# apollo510 register map
Vendor: Ambiq Micro; Series: Apollo; File version: 1.0
CPU: CM55 r1p1, little endian, MPU, FPU, double-precision FPU, DSP, I-cache, D-cache, VTOR, ITCM, DTCM, 4 interrupt priority bits, 0 interrupts, 8 SAU regions
Registers are 32-bit, read-write, reset 0x0 unless marked. A register's access mark holds for its fields unless they carry their own. Offsets are from the block's base; [hi:lo] are bit positions; {n}, {i} and the like mark numbered series.

## DSI — Digital Serial Interface Unit
Base 0x400A8000
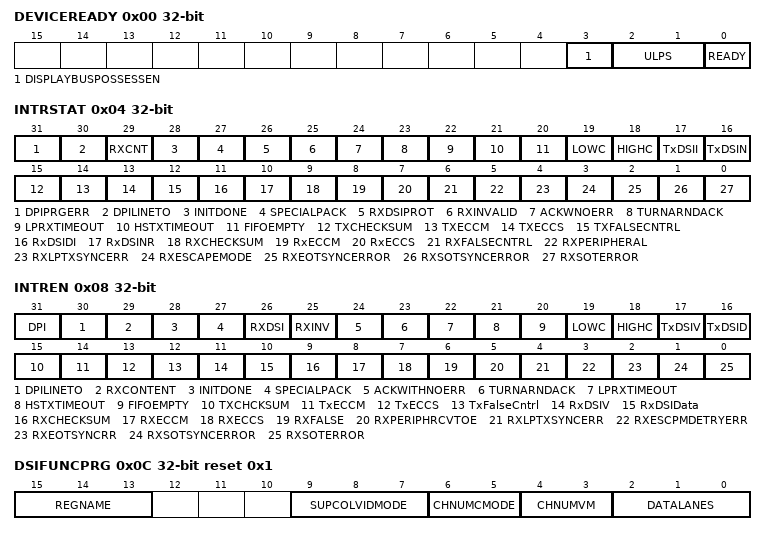
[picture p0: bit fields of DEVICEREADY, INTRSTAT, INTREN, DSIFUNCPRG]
0x00 DEVICEREADY — Devide Ready register
  [3] DISPLAYBUSPOSSESSEN — Inform DSI receiver has to be given the bus possession for receiving the tearing effect trigger message; Reset by the processor to stop the bus possession of the DSI receiver; Note: Tearing effect is supported only in Type1; Display Architecture (command mode only) as suggested by Display Command Set Specification; Note1: Even if the processor does not clear the display_bus_possession bit after receiving the interrupt for tearing effect, DSI-tx controller starts the activities on the DSI link once the TE trigger message is received
  [2:1] ULPS — FIXME - Bitfield description needed here.
    2=LOW_POWER (This pattern is set by the processor to inform that entire DSI host is to be put on ultra low power [POWER SAVING] mode 01 - This pattern is set by the processor to inform); 1=EXIT (This pattern is set by the processor to inform that entire DSI host is to be pu on ultr low power EXIT mode); 0=This (pattern is set by the processor to make the DSI host come out of the wakeup time and resume the normal operation if the DSI Host already remains in the ULPS exit state. S/W needs to ensure that there is a minimum of 1ms time available before clearing the UPLS exit State. 1(a). In DPI Only Mode: No DPI traffic should be sent after the above patterns like 10 or 01 is set in this register. Device_ready bit in Device Ready register should not be disturbed or should remain set while the device is subjected to ULPS states. 1(b). In Dual Display Mode: DPI Interface has to be disabled and also no DBI traffic should be sent after the above patterns like 10 or 01 is set in this register. Device_ready bit in Device Ready register should not be disturbed or should remain set while the device is subjected to ULPS states.)
  [0] READY — Ready for programming after all count registers and timeout.
    1=PROGRAMMED (Set to 1 after dphy_parameter register, all the count registers, and timeout and interrupt enable registers are being programmed.); 0=READY (Set by the processor to inform that device is ready for transmission. This register should be set to 1 after dphy_parameter register, all the count registers, and timeout and interrupt enable registers are being programmed. Note: Reprogramming the registers by resetting the device_ready bit results in re-enumeration of the DSI controller from the power up sequence.)
0x04 INTRSTAT — The interrupt status register.
  [31] DPIPRGERR — (RW1C) Set to 1 indicates that the error in DPI parameters programming
  [30] DPILINETO — (RW1C) DPI line time out. Set to 1 indicates that the line time out during the DPI transfer
  [29] RXCNT — (RW1C) Rx Contention; Set to 1 if contention detected in the display
  [28] INITDONE — (RW1C) Set 1 indicates that the DSI initialization is done. DSI Tx is ready to accept the DPI or DBI or Generic transfer
  [27] SPECIALPACK — (RW1C) Special packet command sent; Set to confirm the transmission of the DPI event specific commands set in the dpi control and dpi data
  [26] RXDSIPROT — (RW1C) Rx DSI protocol violation; Set if acknowledge short packet shows DSI protocol violation error
  [25] RXINVALID — (RW1C) Rx Invalid; Set if acknowledge short packet shows an invalid transmission count
  [24] ACKWNOERR — (RW1C) T ACK_with No_error; Set if acknowledge trigger message is received with out any error.
  [23] TURNARNDACK — (RW1C) Turn around acknowledge. Set if a turn around acknowledgement sequence is timeout not received from the display device
  [22] LPRXTIMEOUT — (RW1C) Set if a low power reception count expires this interrupt is generated
  [21] HSTXTIMEOUT — (RW1C) Set if a high speed transmission prevails for more than the expected count value this interrupt is raised
  [20] FIFOEMPTY — (RW1C) Set to 1 if all FIFOs are empty
  [19] LOWC — (RW1C) Low contention; Set to 1 if a LP low fault is registered by at the D-PHY contention detector. If this interrupt is set device should be re-enumerated
  [18] HIGHC — (RW1C) High contention;Set to 1 if a LP high fault is registered by at the D-PHY contention detector. If this interrupt is set device should be re-enumerated
  [17] TxDSII — (RW1C) TxDSI VC ID invalid; Set to 1 if the received virtual channel ID is invalid
  [16] TxDSIN — (RW1C) TxDSI data type not recognised; Set to 1 if the received data type is not recognised
  [15] TXCHECKSUM — (RW1C) Txchecksum error; Set to 1 if the computed CRC differs from the received CRC value during the reception of packets by Arasan_DSI host
  [14] TXECCM — (RW1C) Set to 1 if there is no ECC correction for the packet or there are more than 2 bit errors in the packet received by Arasan_DSI_host.
  [13] TXECCS — (RW1C) Set to 1 if ECC syndrome was computed and is corrected for one bit error during the reception of packets by the Arasan_DSI_host.
  [12] TXFALSECNTRL — (RW1C) TxFalse Control Error; Set to 1 if a control error is observed on the lanes by the Arasan_DSI_host
  [11] RxDSIDI — (RW1C) RxDSI VC ID invalid; Set to 1 if the virtual channel ID is invalid by the display device is reported in the Acknowledge packet by the display device
  [10] RxDSINR — (RW1C) RxDSI data type not recognised; Set to 1 if the data type is not recognised by the display device is reported in the Acknowledge packet by the display device
  [9] RXCHECKSUM — (RW1C) Set to 1 if the computed CRC differs from the received CRC value and is reported in the acknowledge packet by the display device
  [8] RxECCM — (RW1C) RxECC multibit error; Set to 1 if there is no ECC correction for the packet or there are more than 2 bit errors in the packet isreported in the Acknowledge packet by the display device
  [7] RxECCS — (RW1C) RRxECC single bit error; Set to 1 if ECC syndrome was computed and corrected for one bit error is reported in the Acknowledge packet by the display device
  [6] RXFALSECNTRL — (RW1C) RxFalse Control Error; Set to 1 if a control error is reported in the acknowledge packet by the display device
  [5] RXPERIPHERAL — (RW1C) Rx Peripheral timeout Error; Set to 1 if the high speed receive timer value or LP Tx timer value are expired, display device is reported in the Acknowledge packet
  [4] RXLPTXSYNCERR — (RW1C) Rx LP tx sync error; Set to 1 if Low power transmission sync error occurs in the display device and is reported in the Acknowledge packet by the display device
  [3] RXESCAPEMODE — (RW1C) Entry Error; Set to 1 if Escape Mode Entry command is not understandable by the display device and is reported in the Acknowledge packet by the display device.
  [2] RXEOTSYNCERROR — (RW1C) Set to 1 if End of transmission synchronisation Error is reported in the acknowledgment packet by the display device
  [1] RXSOTSYNCERROR — (RW1C) Set to 1 if synchronisation error occurrence in the start of transmission sequence is reported in the acknowledge packet by the display device
  [0] RXSOTERROR — (RW1C) Set to 1 if a start of transmission sequence error is reported in the Acknowledge packet by the display device
0x08 INTREN — Interrupt enable register.
  [31] DPI — PGRMERR DPI program error; Set to 1 indicates that the error in DPI parameters programming
  [30] DPILINETO — Dpi line timeout; Set to 1 indicates that the line time out during the DPI transfer
  [29] RXCONTENT — Detected Rx Contention Detected; Set to enable the interrupt for contention detected error in the acknowledgment packet reports
  [28] INITDONE — Set 1 indicates that the DSI initialisation is done DSI Tx is ready to accept the DPI or DBI or Generic transfer
  [27] SPECIALPACK — Special packet command sent; Set to enable the confirmation interrupt for transmitting DPI events set in the dpi data and dpi control registers
  [26] RXDSI — Rx DSI protocol violation; Set to enable DSI protocol violation error
  [25] RXINV — Rx Invalid transmission count error; Set to enable acknowledge invalid transmission counterror
  [24] ACKWITHNOERR — ACK with No_error; Set to enable acknowledge trigger message reception with out any error
  [23] TURNARNDACK — Set to enable turn around acknowledgement sequence timeout
  [22] LPRXTIMEOUT — Set to enable low power reception count timeouts
  [21] HSTXTIMEOUT — Set to enable a high speed transmission timeout
  [20] FIFOEMPTY — Set to enable a FIFO empty interrupt
  [19] LOWC — Low contention; Set to enable a LP low fault interrupt
  [18] HIGHC — High contention; Set to enable a LP high fault interrupt
  [17] TxDSIV — TxDSI VC ID invalid; Set to enable the interrupt if the received packets virtual channel ID is invalid
  [16] TxDSID — TxDSI data type not recognised; Set to enable the interrupt if the received packets data type is not recognised
  [15] TXCHCKSUM — Txchecksum error; Set to enable the interrupt if the computed CRC differs from the received CRC value for the received packets
  [14] TxECCM — TxECC multibit; Set to enable the interrupt if there is no ECC correction for the packet or there are more than 2 bit errors in the packet received by Arasan DSI host
  [13] TxECCS — TxECC single bit; Set to enable the interrupt if ECC syndrome was computed and is corrected for one bit error during the reception of packets by the Arasan DSI Host
  [12] TxFalseCntrl — TxFalse Control; Set to enable the interrupt for the control error observed on the lanes by the Arasan_DSI_host
  [11] RxDSIV — RxDSI VC ID invalid virtual channel; Set to enable the interrupt for invalid ID in the acknowledgment packet reports
  [10] RxDSIData — RxDSI data type not recognised; Set to enable the interrupt for the un recognised data type in the acknowledgment packet reports
  [9] RXCHECKSUM — Rxchecksum error; Set to enable the interrupt for the computed CRC differs from the received CRC value in the acknowledgment packet reports
  [8] RXECCM — RxECC multibit error; Set to enable the interrupt for no ECC correction for the packet or there are more than 2 bit errors reported in the acknowledgment packet
  [7] RXECCS — RxECC single bit error; Set to enable the interrupt for ECC syndrome computation and one bit error correction for the acknowledgment packet
  [6] RXFALSE — RxFalse Control error; set to enable the interrupt for control error in the acknowledgment packet reports.
  [5] RXPERIPHRCVTOE — Peripheral receive timeout Error; Set to enable the interrupt for the high speed timeout Error or Lp tx timeout error in the acknowledgment packet reports
  [4] RXLPTXSYNCERR — Rx LP tx sync error; Set to enable the interrupt for Low power transmission sync error in the acknowledgment packet reports
  [3] RXESCPMDETRYERR — RxEscape Mode Entry Error; Set to enable the interrupt for Escape Mode Entry command error in the acknowledgment packet reports
  [2] RXEOTSYNCRR — RxEot Sync Error l set to enable the interrupt for the end of transmission synchronisation Error in the acknowledgment packet reports
  [1] RXSOTSYNCERROR — RX start of transmission; Set to enable the interrupt for start of transmission synchronization error in the acknowledgement packet reports
  [0] RXSOTERROR — RX start of transmission; set to enable the interrupt for start of transmission
0x0C DSIFUNCPRG reset 0x1 — DSI function programming register
  [15:13] REGNAME — FIXME - Bitfield description needed here.
    0=command (mode is not supported]); 1=16BIT0 (16 bit data); 2=9BIT (9 bit data); 3=8BIT (8 bit data); 4=16BIT1 (16 bit mode (option 1))
  [9:7] SUPCOLVIDMODE — Supported colour format for video mode.
    0=FMTVMODE0 (Video mode is not supported); 1=FMTVMODE1 (RGB565 or 16-bit format); 2=FMTVMODE2 (RGB666 or 18-bit format); 3=FMTVMODE3 (RGB 666 loosely packed format); 4=FMTVMODE4 (RGB888 or 24-bit format)
  [6:5] CHNUMCMODE — Channel Number for command mode is programmed by the processor
    {v}=VCCH{v} (Virtual command mode channel {v}) (v=0..3)
  [4:3] CHNUMVM — Channel number for video mode
    {v}=VVCH{v} (Virtual video mode channel {v}) (v=0..3)
  [2:0] DATALANES — The number Data lanes to be supported is programmed by the processor
    0=DATAL0 (FIXME - enum description needed here.); 1=DATAL1 (One data lane); 2=DATAL2 (Two data lane); 3=DATAL3 (Three data lane); 4=DATAL4 (Four data lane)
0x10 HSTXTIMEOUT reset 0xFFFF — Maximum duration allow for the DSi host to remain in High speed mode for transmission.
  [23:0] MAXDURTOCNT — The maximum duration allowed for the DSI host to remain in high speed mode for a transmission. If the counter expires, processor is interrupted with HS_Tx_timeout interrupt
0x14 LPRXTO reset 0xFFFF — Timeout value to be checked for reverse communicationl
  [23:0] TOCHKRVS — Timeout value to be checked for reverse communication. If the counter expires, processor is interrupted with LP_Rx_timeout interrupt.The timeout value is protocol specific. Time out value is calculated from txclkesc(50ns).
0x18 TURNARNDTO reset 0x17 — Timeout value to be checked after the DSI host makes a trun around in the direction of transfers.
  [5:0] TIMOUT — If the counter expires, processor is interrupted with Turn_around_ack timeout interrupt; this specified period shall be longer then the maximum possible turnaround delay for the unit to which the turnaround request was sent, which is 23 clock cycles of txclkesc; any number greater than or equal to 23 is an acceptable number.
0x1C DEVICERESETTIMER reset 0xFF — Timeout value to be checked for device to be reset after issuing reset entry command
  [15:0] TIMOUT — If the timer expires the DSI Host enters normal operation; This time out value is used while contention recovery procedure; the time out value is equal to a value longer than the specified time required to complete the reset sequence
0x20 DPIRESOLUTION — Shows the horizontal address count in pixels
  [31:0] DPIRESOLUTION — TODO: update this register description
0x28 HSYNCCNT — Shows the horizontal sync value in terms of byte clock.
  [15:0] HORZCNT — rw 0000h Shows the horizontal sync value in terms of byte clock (txbyteclkhs); Minimum HSA period should be sufficient to transmit a Hsync start short packet(4 bytes) i) For Non-burst Mode with sync pulse, Min value - 4 in decimal (plus an optional 6 bytes for a zero payload blanking packet); But if the value is less than 10 but more than 4, then this count will be added to the HBP's count for one lane; ii) For Non-Burst Sync Event and Burst Mode, there is no HSA, so you can program this to zero. If you program this register, these byte values will be added to HBP Max value - any 12 bit value greater than 4 based on DPI resolution
0x2C HORIZBKPORCHCNT — Shows the horizontal back porch value in terms of txbyteclkhs.
  [15:0] HORZBKPCNT — For Non Burst Sync pulse mode, for one lane. Minimum HBP count = Hsync End short packet + HBP Blanking packet overhead (header(4) + crc (2)) + RGB packet header For other lane counts minimum value = Minimum HBPcount / lane_count. For Non Burst Sync event / Burst Mode there is no HSA. Minimum HBP count = (Hsync Start short packet + HBP Blanking packet overhead + RGB packet header) / lane_count Min value - 14 in decimal (accounted with zero payloads for blanking packet] for one lane. Max value - any 12 bit value greater than 14 based on DPI resolution
0x30 HORIZFPORCHCNT — Shows the horizontal front porch value in terms of txbyteclkhs.
  [15:0] HORZFTPCNT — Minimum HFP period should be sufficient to transmit RGB Data packet footer (2 bytes) + Blanking packet overhead (6 bytes) +adjustable count (16 bytes) for non burst mode; For other lane counts Minimum value = (RGB Data packet footer(2 bytes) + Blanking packet overhead(6 bytes)) / (lane_count) + adjustable count(16 bytes) For burst mode, Minimum HFP period should be sufficient to transmit Blanking packet overhead(6 bytes) +adjustable count (16 bytes) for one lane for other lane counts Minimum value = ( Blanking packet overhead(6 bytes)) / (lane_count) + adjustable count(16 bytes) Min value - 8 in decimal for non-burst mode (accounted with zero payload for blanking packet) for one lane Min value - 6 in decimal for burst mode for one lane Max value - any 12 bit value greater than the minimum value based on DPI resolution; Minimum HFP period should be sufficient to transmit
0x34 HORZACTIVEAREACNT — Horizontal active area count / time for active image data / Horizontal Address
  [15:0] HORACTCNT — Shows the horizontal active area value in terms of txbyteclkhs. In Non Burst Mode, Count equal to RGB word count value In Burst Mode, RGB pixel packets are time compressed, leaving more time during a scan line for LP mode (saving power) or for multiplexing other transmissions onto the DSI link. Hence, the count equals the time in txbyteclkhs for sending time compressed RGB pixels plus the time needed for moving to power save mode or the time needed for secondary channel to use the DSI link. But if the left out time for moving to low power mode is less than 8 txbyteclkhs (2txbyteclkhs for RGB data packet footer and 6txbyteclkhs for a blanking packet with zero payload), then this count will be added to the HFPs count for one lane.
0x38 VSYNCCNT — Shows the vertical sync value
  [15:0] VSC — Shows the vertical sync value in terms of lines. Min value - 2 Max value - any 12 bit value greater than 2 based on DPI resolution
0x3C VERTBKPORCHCNT — Shows the vertical back porch value
  [15:0] VBPSC — Shows the vertical back porch value in terms of lines. Min value - 1; Max value - any 12 bit value greater than 1 based on DPI resolution
0x40 VERTFPORCHCNT — Shows the vertical front porch value
  [15:0] VFPSC — Shows the vertical front porch value in terms of lines. Min value - 1; Max value - any 12 bit value greater than 1 based on DPI resolution
0x44 DATALANEHILOSWCNT — High speed to low power or Low power to high speed switching time
  [15:0] DATALHLSWCNT — High speed to low power or Low power to high speed power or Low switching time in terms byte clock (txbyteclkhs). This power to high speed switch count value is based on the byte clock (txbyteclkhs) and low power clock frequency (txclkesc); Data lane Switch count = 4 * Tlpx + programmed THS_prep + programmed THS_zero + 4 byteclk Tlpx = Low power clock equivalence in of terms byte clock programmed in AHB reg 68h; THS_prep = programmed value of dln_cnt_hs_prep in AHB Reg 6ch bit (7:0) THS_zero = programmed value of dln_cnt_hs_zero in AHB Reg 6ch bit (15:8) Programmable count should be equal or greater than this value. Typical value x96 Number of byte clocks required to switch from low power mode to high speed mode after txrequesths is asserted.
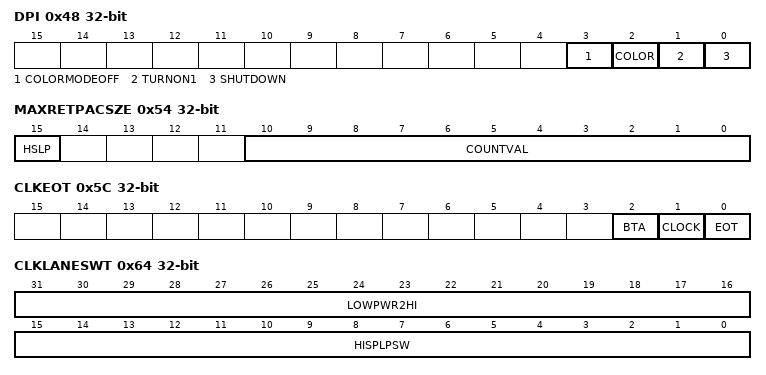
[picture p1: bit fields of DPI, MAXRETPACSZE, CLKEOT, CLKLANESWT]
0x48 DPI — DPI control register.
  [3] COLORMODEOFF — Set to 1 to indicate a Color Mode OFF short packet has to be packetised for the DPIs virtual channel
  [2] COLOR — MODEON Set to 1 to indicate a color Mode ON short packet has to be packetised for the DPIs virtual channel.
  [1] TURNON1 — Set to 1 to indicate a Turn ON short packet has to be packetised for the DPIs virtual channel
  [0] SHUTDOWN — Set to 1 to indicate a shut down short packet has to be packetised for the DPIs virtual channel
0x4C PLLLOCKCNT reset 0x7D0 — The PLL counter value
  [15:0] PLLCNTVAL — Pll counter value in terms of low power clock.
0x50 INITCNT reset 0x7D0 — Count register to initialize the DSI HOST IP
  [15:0] MSTR — Counter value in terms of low power clock to initialise the DSI Host IP (TINIT) that drives a stop state on the mipis D-PHY bus; DPHY Initialization period min 100 x B5s; Time out value is calculated by txclkesc and the count value is 7d0h(2000 in decimal)
0x54 MAXRETPACSZE — FIXME - Register description needed here.
  [15] HSLP — Indicates the data transfer type
  [10:0] COUNTVAL — Set the count value in bytes to collect the return data packet for reverse direction data flow in data lane0 in response to a DBI read operation; Count value equals the maximum size of the payload in a Long packet transmitted from peripheral back to; for DBI and DPI interleaving Min value - 1; Max value - Maximum payload for a long packet size is 1K bytes Note: DCS short Read Response or Long read response with 1 or 2 parameters is applicable in this mode; For DBI only, Min value - 1 Max value - Maximum payload for a long packet size is 1K bytes
0x58 VIDEOMODEFMT — Sets the Video mode format (packet sequence) to be supported in DSI.
  [1:0] VIDEMDFMT — Sets the Video mode format (packet sequence) to be supported in DSI; in Non Burst Mode, in addition to programming this register the horizontal active area count register value should also be programmed equal to RGB word count value; in Burst Mode, in addition to programming this register the horizontal active area count register value should also be programmed greater than the RGB word count value, leaving more time during a scan line for LP mode (saving power) or for multiplexing other transmissions onto the DSI link;
    0=FIXME_ENUM (FIXME - enum description needed here.); 1=NONBURSTPULSE (Non Burst Mode with Sync Pulse); 2=NONBURSTEVENTS (Non Burst Mode with Sync events); 3=BURST (MODE Burst Mode)
0x5C CLKEOT — The EOT clock register disables the video.
  [2] BTA — Disable video; Set by the processor to inform the DSI controller to disable the BTA sent at the last blanking line of VFP. By default, this bit is set to 0; 0 BTA sending at the last blanking line of VFP is enabled; 1 BTA sending at the last blanking line of VFP is disabled
  [1] CLOCK — Set by the processor to enable or disable clock; Stopping feature during BLLP timing in a DPI transfer in dual channel mode or during DPI only mode and also when there is no traffic in the DBI interface in DBI only enabled mode. By default this register value is 0.
  [0] EOT — Set by the processor to enable or disable EOT short disable_register packet transmission; vy default this register value is 0; for backward compatibility of earlier DSI systems, EOT short packet transmission can be disabled; 0 EOT short packet transmission enabled, 1 EOT short packet transmission disabled
0x60 POLARITY
  [3:0] PBITS — Polarity bits
    0=POLV (polarity for Vsync); 1=POLH (Polarity for Hsync); 2=POLSD (Polarity for shut down); 3=POLCM (Polarity for Color mode)
0x64 CLKLANESWT — High speed to low power switching time in terms ofbyte clock (txbyteclkhs)
  [31:16] LOWPWR2HI — This value is based on the byte clock (txbyteclkhs) and low power clock frequency (txclkesc)LP to HS switch count = 4 * Tlpx + (programmed Tclk_prep + extracount (1 byteclk) ) + (programmed Tclk_zero + extracount (1 byteclk) ) + Tclk_pre + 2 byteclk Tlpx = Low power clock equivalence in terms of byte clock programmed in AHB reg 68h Tclk_prep = programmed value of cln_cnt_prep in AHB Reg 70h bit (7:0) Tclk_zero = programmed value of cln_cnt_zero in AHB Reg 70h bit (15:8) Tclk_pre = 8 UI Typical value x96 Number of byte clocks required to switch from low power mode to high speed mode after txrequesths_clk is asserted.
  [15:0] HISPLPSW — High speed to low power switching time in terms byte clock (txbyteclkhs). This value is based on the byte clock (txbyteclkhs) and low power clock frequency; HS to LP switch count = Tclk_trail + THS_Exit + 3 byteclk Tclk_trail = programmed value of cln_cnt_hs_trail in AHB Reg 70h bit (23:16) THS_Exit = programmed value of cln_cnt_hs_exit in AHB Reg 70h bit (31:24) Typical value - Number of byte clocks request to switch from high speed mode to low power mode after txrequesths_clk is de-asserted.
0x68 LPBYTECLK reset 0x1 — Low power clock equivalence in terms of byte clock.
  [15:0] VALBYTECLK — The value programmed in this register is equal to the number of byte clocks occupied in one low power clock; this value is based on the byte clock (txbyteclkhs) and low power clock frequency (txclkesc)
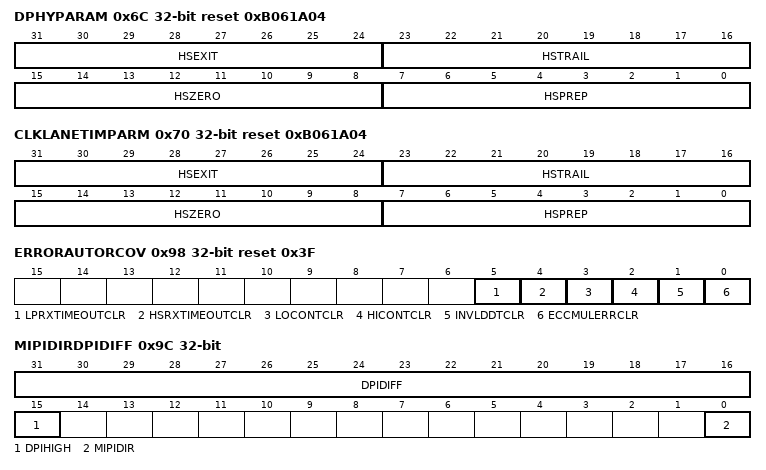
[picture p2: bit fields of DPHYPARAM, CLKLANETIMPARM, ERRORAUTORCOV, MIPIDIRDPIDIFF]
0x6C DPHYPARAM reset 0xB061A04 — This field provides the timing requirement in byte clocks for the high speed preparation time.
  [31:24] HSEXIT — This field provides the timing requirement in byte clocks for the high speed exit time; this corresponds to the THS-EXIT parameter specified in the DPHY specification
  [23:16] HSTRAIL — This field provides the timing requirement in byte clocks for the high speed trail time; this corresponds to the THS-TRAIL parameter specified in the DPHY specification
  [15:8] HSZERO — This field provides the timing requirement in byte clocks for the high speed drive zero time. This corresponds to the THS-ZERO parameter specified in the DPHY specification
  [7:0] HSPREP — This field provides the timing requirement in byte clocks for the high speed preparation time. This corresponds to the THS-PREP parameter specified in the DPHY specificaton
0x70 CLKLANETIMPARM reset 0xB061A04 — This field provides the timing requirement in byte clocks
  [31:24] HSEXIT — This field provides the timing requirement in byte clocks for the high speed exit time; This corresponds to the THS-EXIT parameter specified in the DPHY specification.
  [23:16] HSTRAIL — This field provides the timing requirement in byte clocks for the high speed trail time; This corresponds to the TCLK-TRAIL parameter specified in the DPHY specification
  [15:8] HSZERO — This field provides the timing requirement in byte clocks for the high speed drive zero time; this corresponds to the TCLK-ZERO parameter specified in the DPHY specification
  [7:0] HSPREP — This field provides the timing requirement in byte corresponds to the TCLK-PREP parameter specified in the DPHY specificatio
0x74 RSTENBDFE — This field provides the reset (enable) to the DFE
  [0] ENABLE — This field provides the reset (enable) to the DFE.
0x78 AFETRIM0 reset 0x1A000615 — Afe Trim reg0
  [31:0] AFETRIM0 — Afe Trim reg0.
0x7C AFETRIM1 reset 0x15640152 — Afe Trim reg1
  [31:0] AFETRIM1 — Afe Trim reg1.
0x80 AFETRIM2 reset 0x10000000 — Afe Trim reg2
  [31:0] AFETRIM2 — Afe Trim reg2.
0x84 AFETRIM3 reset 0x40F8 — Afe Trim reg3
  [31:0] AFETRIM3 — Afe Trim reg3.
0x98 ERRORAUTORCOV reset 0x3F — Errir ayti recivert register
  [5] LPRXTIMEOUTCLR — If this bit is set to 1, lp_rx_timeout_clr error recovery action is taken immediately by DSI TX
  [4] HSRXTIMEOUTCLR — If this bit is set to 1, Hs_rx_timeout_clr error recovery action is taken immediately by DSI TX
  [3] LOCONTCLR — If this bit is set to 1, lo_cont_clr error recovery action is taken immediately by DSI TX
  [2] HICONTCLR — If this bit is set to 1, Hi_cont_clr error recover action is taken immediately by DSI TX
  [1] INVLDDTCLR — If this bit is set to 1, Invld_dt_clr error recovery action is taken immediately by DSI TX
  [0] ECCMULERRCLR — if this bit is set to 1, Ecc_mul_err_clr error recovery action is taken immediately by DSI TX
0x9C MIPIDIRDPIDIFF — Mipi direction DPI difference
  [31:16] DPIDIFF — This field provides the difference in one line time between DPI and DSI
  [15] DPIHIGH — This field provides information to check DPI line time is greater or DSI line time is greater
    0=LESSTHAN (one line time in DPI is less than to DSI line time); 1=GREATER (one line time in DPI is greater than or equal to DSI line time)
  [0] MIPIDIR — This field provides the direction of MIPI bus;
    0=CONTROL (DSI Host has the control over MIPI bus); 1=RECEIVE (DSI Host is in Receive mode)
0xA0 DATALANEPOLSWAP — Data lane polarity swap register
  [3:0] DATALNPOLSWAP — Data lane Polarity sw
    1=LANE0 (lane 0 polarity swap); 2=LANE1 (lane 1 polarity swap); 4=LANE2 (lane 2 polarity swap); 8=LANE3 (lane 3 polarity swap); 15=ALLLANES (data lanes polarity swap)
